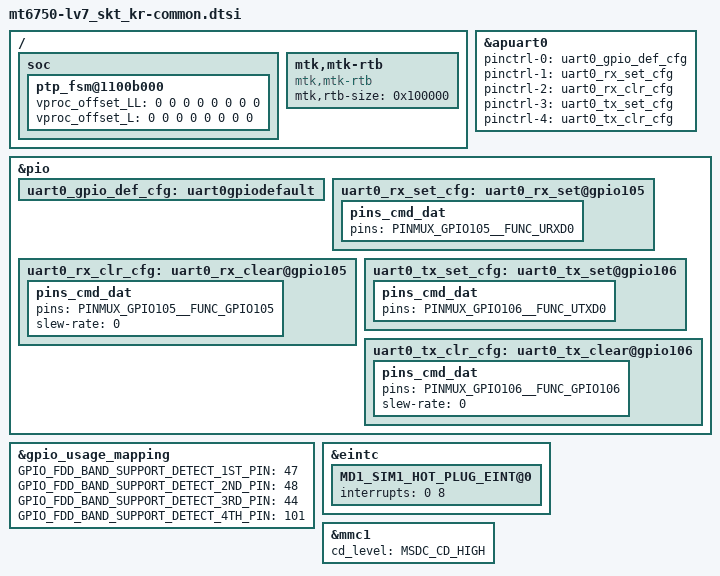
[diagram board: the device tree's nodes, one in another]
/*
 * LG Electronics LV7 common device tree source
 *
 * Copyright (c) 2016 LG Electronics Co., Ltd.
 *              http://www.lge.com
 *
 */

/ {
    soc {
        ptp_fsm@1100b000 {
            vproc_offset_LL = <0 0 0 0 0 0 0 0>;
            vproc_offset_L = <0 0 0 0 0 0 0 0>;
        };
    };
};


/* UART GPIO */
&apuart0 {
	pinctrl-names = "uart0_gpio_default",
			"uart0_rx_set",
			"uart0_rx_clear",
			"uart0_tx_set",
			"uart0_tx_clear";
	pinctrl-0 = <&uart0_gpio_def_cfg>;
	pinctrl-1 = <&uart0_rx_set_cfg>;
	pinctrl-2 = <&uart0_rx_clr_cfg>;
	pinctrl-3 = <&uart0_tx_set_cfg>;
	pinctrl-4 = <&uart0_tx_clr_cfg>;
	status = "okay";
};

&pio {
	/* UART GPIO Settings - Start */
	/* UART0: rx set, rx clear, tx clear, tx clear*/
	uart0_gpio_def_cfg:uart0gpiodefault {

	};
	uart0_rx_set_cfg:uart0_rx_set@gpio105 {
		pins_cmd_dat {
			pins = <PINMUX_GPIO105__FUNC_URXD0>;
		};
	};
	uart0_rx_clr_cfg:uart0_rx_clear@gpio105  {
		pins_cmd_dat {
			pins = <PINMUX_GPIO105__FUNC_GPIO105>;
			slew-rate = <0>; //input
			/delete-property/ output-high;
		};
	};
	uart0_tx_set_cfg:uart0_tx_set@gpio106  {
		pins_cmd_dat {
			pins = <PINMUX_GPIO106__FUNC_UTXD0>;
		};
	};
	uart0_tx_clr_cfg:uart0_tx_clear@gpio106  {
		pins_cmd_dat {
			pins = <PINMUX_GPIO106__FUNC_GPIO106>;
			slew-rate = <0>;  // input
			/delete-property/ output-high;
		};
	};
};/* UART GPIO end */

/ {
	mtk,mtk-rtb {
		compatible = "mtk,mtk-rtb";
		mtk,rtb-size = <0x100000>;
	};
};

/* LGE_KERNEL_S, For DRDI */
&gpio_usage_mapping {
	GPIO_FDD_BAND_SUPPORT_DETECT_1ST_PIN = <47>;
	GPIO_FDD_BAND_SUPPORT_DETECT_2ND_PIN = <48>;
	GPIO_FDD_BAND_SUPPORT_DETECT_3RD_PIN = <44>;
	GPIO_FDD_BAND_SUPPORT_DETECT_4TH_PIN = <101>;
};
/* LGE_KERNEL_E */

/* LGE_UICC_S, change detect level{ */
&eintc {
	MD1_SIM1_HOT_PLUG_EINT@0 {
		interrupts = <0 8>;
	};
};
/* LGE_UICC_E } */

&mmc1 {
	cd_level = /bits/ 8 <MSDC_CD_HIGH>;
};
